# CC13x0 register map
File version: 2.0
CPU: CM3 r2p1, little endian, no MPU, no FPU, 3 interrupt priority bits
Registers are 32-bit, read-write, reset 0x0 unless marked. A register's access mark holds for its fields unless they carry their own. Offsets are from the block's base; [hi:lo] are bit positions; {n}, {i} and the like mark numbered series.

## AUX_SCE — AUX Sensor Control Engine Control Module
Base 0x400E1000
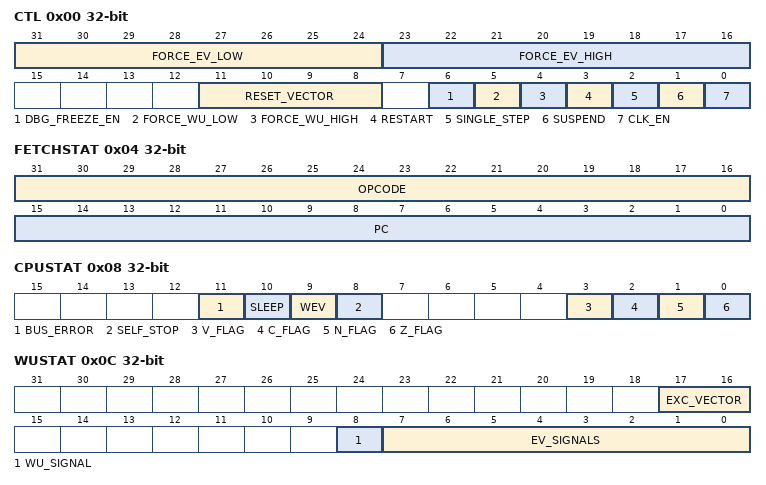
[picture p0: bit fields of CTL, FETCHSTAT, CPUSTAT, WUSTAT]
0x00 CTL — Internal. Only to be used through TI provided API.
  [31:24] FORCE_EV_LOW, [23:16] FORCE_EV_HIGH, [11:8] RESET_VECTOR, [6] DBG_FREEZE_EN, [5] FORCE_WU_LOW, [4] FORCE_WU_HIGH, [3] RESTART, [2] SINGLE_STEP, [1] SUSPEND, [0] CLK_EN
0x04 FETCHSTAT ro — Internal. Only to be used through TI provided API.
  [31:16] OPCODE, [15:0] PC
0x08 CPUSTAT ro — Internal. Only to be used through TI provided API.
  [11] BUS_ERROR, [10] SLEEP, [9] WEV, [8] SELF_STOP, [3] V_FLAG, [2] C_FLAG, [1] N_FLAG, [0] Z_FLAG
0x0C WUSTAT ro — Internal. Only to be used through TI provided API.
  [17:16] EXC_VECTOR, [8] WU_SIGNAL, [7:0] EV_SIGNALS
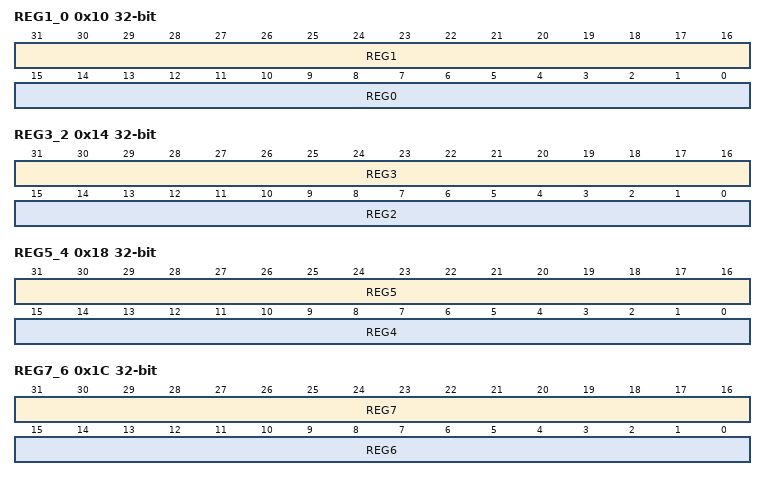
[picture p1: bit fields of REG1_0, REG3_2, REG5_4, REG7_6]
0x10 REG1_0 ro — Internal. Only to be used through TI provided API.
  [31:16] REG1, [15:0] REG0
0x14 REG3_2 ro — Internal. Only to be used through TI provided API.
  [31:16] REG3, [15:0] REG2
0x18 REG5_4 ro — Internal. Only to be used through TI provided API.
  [31:16] REG5, [15:0] REG4
0x1C REG7_6 ro — Internal. Only to be used through TI provided API.
  [31:16] REG7, [15:0] REG6
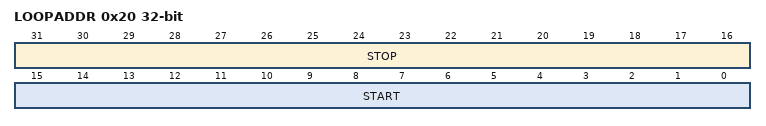
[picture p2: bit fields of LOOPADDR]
0x20 LOOPADDR ro — Internal. Only to be used through TI provided API.
  [31:16] STOP, [15:0] START
0x24 LOOPCNT ro — Internal. Only to be used through TI provided API.
  [7:0] ITER_LEFT

## AUX_SMPH — AUX Semaphore Controller
Base 0x400C8000
{0x0+4i} SMPH{i} reset 0x1 (i=0..7) — Semaphore {i}
  [0] STAT
0x20 AUTOTAKE — Sticky Request For Single Semaphore
  [2:0] SMPH_ID

## AUX_TDCIF — AUX Time To Digital Converter
Base 0x400C4000
0x00 CTL — Control
  [1:0] CMD
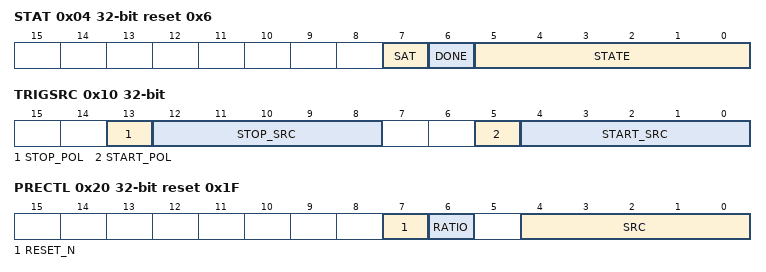
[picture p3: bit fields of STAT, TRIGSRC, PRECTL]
0x04 STAT ro reset 0x6 — Status
  [7] SAT, [6] DONE, [5:0] STATE
0x08 RESULT ro reset 0x2 — Result Result of last TDC conversion
  [24:0] VALUE
0x0C SATCFG reset 0xF — Saturation Configuration
  [3:0] LIMIT
0x10 TRIGSRC — Trigger Source TDC start/stop trigger source selection
  [13] STOP_POL, [12:8] STOP_SRC, [5] START_POL, [4:0] START_SRC
0x14 TRIGCNT — Trigger Counter Stop counter status/control of TDC
  [15:0] CNT
0x18 TRIGCNTLOAD — Trigger Counter Load Stop counter control of TDC
  [15:0] CNT
0x1C TRIGCNTCFG — Trigger Counter Configuration
  [0] EN
0x20 PRECTL reset 0x1F — Prescaler Control The prescaler can be used to count events that are faster than the AUX clock speed. It can be used standalone or as a start/stop source for the TDC by configuring TRIGSRC.START_SRC and TRIGSRC.STOP_SRC to TDC_PRE. When counting fast signals with the TDC that are faster than 1/10th of the clock frequency of AUX it is recommended to use the prescaler.
  [7] RESET_N, [6] RATIO, [4:0] SRC
0x24 PRECNT — Prescaler Counter Value of prescaler counter
  [15:0] CNT

## AUX_TIMER
Base 0x400C7000
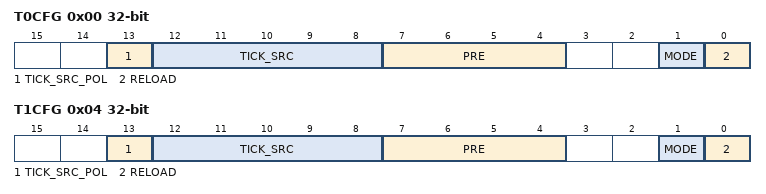
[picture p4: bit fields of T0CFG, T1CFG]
0x00 T0CFG — Timer 0 Configuration
  [13] TICK_SRC_POL, [12:8] TICK_SRC, [7:4] PRE, [1] MODE, [0] RELOAD
0x04 T1CFG — Timer 1 Configuration
  [13] TICK_SRC_POL, [12:8] TICK_SRC, [7:4] PRE, [1] MODE, [0] RELOAD
0x08 T0CTL — Timer 0 Control Run control/status for timer 0
  [0] EN
0x0C T0TARGET — Timer 0 Target Target counter value for timer 0
  [15:0] VALUE
0x10 T1TARGET — Timer 1 Target Target Counter Value Timer 1
  [7:0] VALUE
0x14 T1CTL — Timer 1 Control Run Control/Status For Timer 1
  [0] EN

## CPU_TIPROP — Cortex-M's TI proprietary registers
Base 0xE00FE000
0xFF8 TRACECLKMUX — Internal. Only to be used through TI provided API.
  [0] TRACECLK_N_SWV
0xFFC DYN_CG — Internal. Only to be used through TI provided API.
  [1:0] DYN_CG

## GPIO — MCU GPIO - I/F for controlling and reading IO status and IO event status
Base 0x40022000
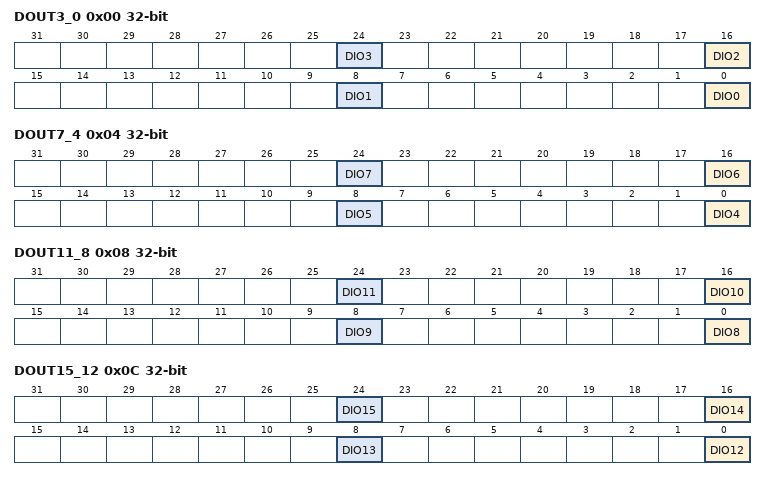
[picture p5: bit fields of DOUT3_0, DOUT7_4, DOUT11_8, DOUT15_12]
0x00 DOUT3_0 — Data Out 0 to 3 Alias register for byte access to each bit in DOUT31_0
  [8n] DIO{n} (n=0..3)
0x04 DOUT7_4 — Data Out 4 to 7 Alias register for byte access to each bit in DOUT31_0
  [8n-32] DIO{n} (n=4..7)
0x08 DOUT11_8 — Data Out 8 to 11 Alias register for byte access to each bit in DOUT31_0
  [8n-64] DIO{n} (n=8..11)
0x0C DOUT15_12 — Data Out 12 to 15 Alias register for byte access to each bit in DOUT31_0
  [8n-96] DIO{n} (n=12..15)
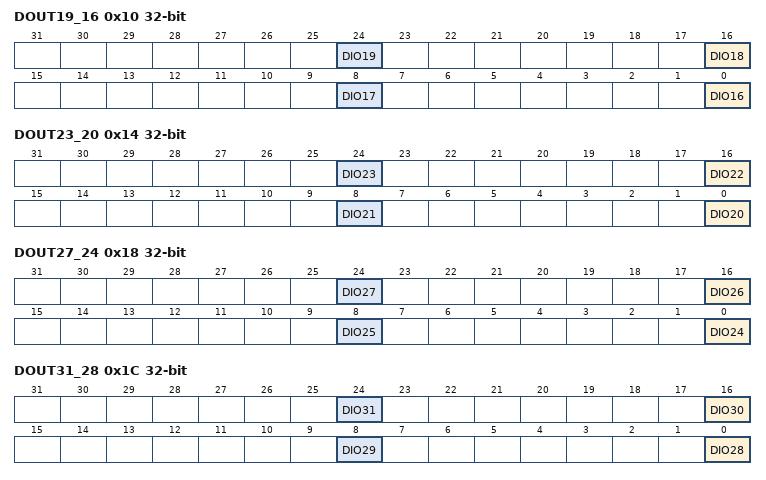
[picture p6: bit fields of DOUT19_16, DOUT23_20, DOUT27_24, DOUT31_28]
0x10 DOUT19_16 — Data Out 16 to 19 Alias register for byte access to each bit in DOUT31_0
  [8n-128] DIO{n} (n=16..19)
0x14 DOUT23_20 — Data Out 20 to 23 Alias register for byte access to each bit in DOUT31_0
  [8n-160] DIO{n} (n=20..23)
0x18 DOUT27_24 — Data Out 24 to 27 Alias register for byte access to each bit in DOUT31_0
  [8n-192] DIO{n} (n=24..27)
0x1C DOUT31_28 — Data Out 28 to 31 Alias register for byte access to each bit in DOUT31_0
  [8n-224] DIO{n} (n=28..31)
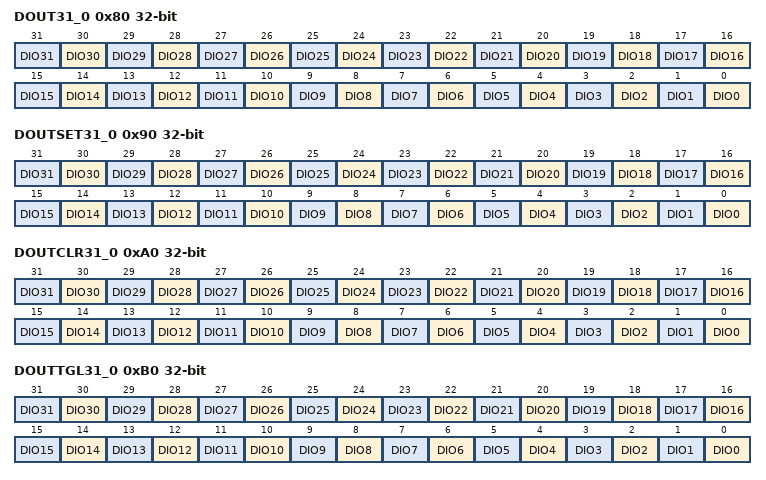
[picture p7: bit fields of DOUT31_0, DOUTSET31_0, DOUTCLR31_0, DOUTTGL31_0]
0x80 DOUT31_0 — Data Output for DIO 0 to 31
  [n] DIO{n} (n=0..31)
0x90 DOUTSET31_0 wo — Data Out Set Writing 1 to a bit position sets the corresponding bit in the DOUT31_0 register
  [n] DIO{n} write-1-sets (n=0..31)
0xA0 DOUTCLR31_0 wo — Data Out Clear Writing 1 to a bit position clears the corresponding bit in the DOUT31_0 register
  [n] DIO{n} write-1-clears (n=0..31)
0xB0 DOUTTGL31_0 — Data Out Toggle Writing 1 to a bit position will invert the corresponding DIO output.
  [n] DIO{n} (n=0..31)
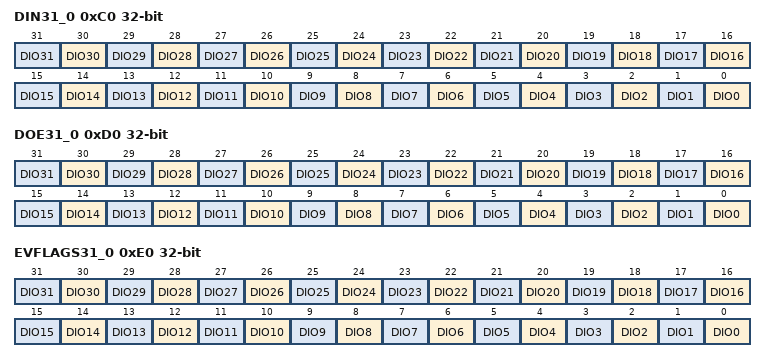
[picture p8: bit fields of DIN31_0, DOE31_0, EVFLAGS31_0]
0xC0 DIN31_0 ro — Data Input from DIO 0 to 31
  [n] DIO{n} (n=0..31)
0xD0 DOE31_0 — Data Output Enable for DIO 0 to 31
  [n] DIO{n} (n=0..31)
0xE0 EVFLAGS31_0 — Event Register for DIO 0 to 31 Reading this registers will return 1 for triggered event and 0 for non-triggered events. Writing a 1 to a bit field will clear the event. The configuration of events is done inside MCU IOC, e.g. events for DIO #0 is configured in IOC:IOCFG0.EDGE_DET and IOC:IOCFG0.EDGE_IRQ_EN.
  [n] DIO{n} write-1-clears (n=0..31)
